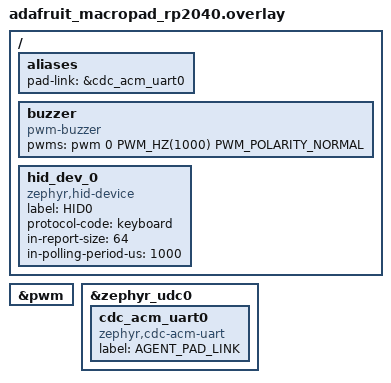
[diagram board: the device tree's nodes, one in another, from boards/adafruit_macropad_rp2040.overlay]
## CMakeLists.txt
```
# SPDX-License-Identifier: Apache-2.0

cmake_minimum_required(VERSION 3.20.0)
find_package(Zephyr REQUIRED HINTS $ENV{ZEPHYR_BASE})
project(agent_pad)

include(${ZEPHYR_BASE}/samples/subsys/usb/common/common.cmake)
target_sources(app PRIVATE
  src/main.c
  src/state.c
  src/keymap.c
  src/link.c
  src/ui.c
)

if(CONFIG_AGENT_PAD_SIM)
  target_sources(app PRIVATE src/sim.c)
else()
  target_sources(app PRIVATE
    src/hid_kb.c
    src/leds.c
    src/chime.c
    src/agent_pad_font_12.c
  )
endif()
```

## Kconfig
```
# SPDX-License-Identifier: Apache-2.0

config AGENT_PAD_SIM
	bool "Simulator GUI instead of pad hardware I/O"
	help
	  Replace the USB HID keyboard, LED strip and buzzer with an
	  interactive LVGL mock of the pad: clickable key and encoder
	  widgets, live agent-key colors and indicators for the keystrokes
	  and chimes the firmware would emit. The serial link protocol stays
	  active, making the whole application testable without hardware,
	  e.g. on qemu_x86.

# Source common USB sample options used to initialize new experimental USB
# device stack. The scope of these options is limited to USB samples in project
# tree, you cannot use them in your own application.
source "samples/subsys/usb/common/Kconfig.sample_usbd"

source "Kconfig.zephyr"
```

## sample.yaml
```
sample:
  name: Agent Pad
  description: Agent control surface with live status keys for AI coding agents
tests:
  sample.boards.adafruit.macropad_rp2040.agent_pad:
    build_only: true
    modules:
      - lvgl
    platform_allow:
      - adafruit_macropad_rp2040
    integration_platforms:
      - adafruit_macropad_rp2040
    tags:
      - usb
      - input
      - display
      - led_strip
  sample.boards.adafruit.macropad_rp2040.agent_pad.sim:
    build_only: true
    modules:
      - lvgl
    platform_allow:
      - qemu_x86
    integration_platforms:
      - qemu_x86
    tags:
      - display
      - input
```

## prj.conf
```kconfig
CONFIG_LOG=y

CONFIG_USB_DEVICE_STACK_NEXT=y
CONFIG_USBD_LOG_LEVEL_WRN=y
CONFIG_UDC_DRIVER_LOG_LEVEL_WRN=y
CONFIG_SAMPLE_USBD_PID=0x0007
CONFIG_SAMPLE_USBD_PRODUCT="Agent Pad"
CONFIG_HWINFO=y
CONFIG_UART_INTERRUPT_DRIVEN=y
CONFIG_UART_LINE_CTRL=y

CONFIG_GPIO=y
CONFIG_INPUT=y

CONFIG_SPI=y
CONFIG_DISPLAY=y

CONFIG_LVGL=y
CONFIG_LV_Z_MEM_POOL_SIZE=16384
CONFIG_LV_COLOR_DEPTH_1=y
# The SH1106 is vertically tiled, so LVGL can only flush whole 8-row pages.
# The default 10% rendering buffer is not even one page tall, which makes
# LVGL give up and leave the panel showing its uninitialized RAM. A full
# frame is only 1 KiB here, so render the whole screen at once.
CONFIG_LV_Z_VDB_SIZE=100
CONFIG_LV_USE_LABEL=y
# The UI draws with the 1 bpp agent_pad_font_12. LVGL still needs a default
# font to exist, so pick the smallest built-in one rather than link an
# antialiased face that nothing ends up rendering.
CONFIG_LV_FONT_DEFAULT_UNSCII_8=y

CONFIG_LED_STRIP=y

CONFIG_PWM=y
CONFIG_BUZZER=y
CONFIG_REGULATOR=y

CONFIG_HEAP_MEM_POOL_SIZE=4096
CONFIG_MAIN_STACK_SIZE=4096
CONFIG_SYSTEM_WORKQUEUE_STACK_SIZE=4096
```

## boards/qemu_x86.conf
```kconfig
CONFIG_AGENT_PAD_SIM=y

# No pad hardware in QEMU
CONFIG_USB_DEVICE_STACK_NEXT=n
CONFIG_SPI=n
CONFIG_LED_STRIP=n
CONFIG_PWM=n
CONFIG_BUZZER=n
CONFIG_REGULATOR=n
CONFIG_HWINFO=n

# The virtio tablet reports a burst of events at boot
CONFIG_INPUT_QUEUE_MAX_MSGS=64

# Color framebuffer, mouse-clickable widgets. The tiling constraint that
# forces a full-frame buffer on the OLED does not apply here, and a full
# 480x272 buffer at 32 bpp would be half a megabyte.
CONFIG_LV_COLOR_DEPTH_32=y
CONFIG_LV_Z_VDB_SIZE=10
# Greyscale is available here, so use the antialiased face instead of the
# 1 bpp font the OLED needs.
CONFIG_LV_FONT_MONTSERRAT_12=y
CONFIG_LV_FONT_DEFAULT_MONTSERRAT_12=y
CONFIG_LV_USE_BUTTON=y
CONFIG_LV_Z_POINTER_FROM_CHOSEN_TOUCH=y
CONFIG_LV_Z_MEM_POOL_SIZE=131072

# Wall-clock timing for interactive use; link protocol on the second
# serial port, exposed by QEMU as a pty
CONFIG_QEMU_ICOUNT=n
CONFIG_QEMU_EXTRA_FLAGS="-serial pty"
```

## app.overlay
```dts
/*
 * Copyright The Zephyr Project Contributors
 *
 * SPDX-License-Identifier: Apache-2.0
 */

#include <zephyr/dt-bindings/pwm/pwm.h>

/ {
	buzzer: buzzer {
		compatible = "pwm-buzzer";
		pwms = <&pwm 0 PWM_HZ(1000) PWM_POLARITY_NORMAL>;
	};

	hid_dev_0: hid_dev_0 {
		compatible = "zephyr,hid-device";
		label = "HID0";
		protocol-code = "keyboard";
		in-report-size = <64>;
		in-polling-period-us = <1000>;
	};
};

&pwm {
	status = "okay";
};

&zephyr_udc0 {
	cdc_acm_uart0: cdc_acm_uart0 {
		compatible = "zephyr,cdc-acm-uart";
		label = "AGENT_PAD_LINK";
	};
};
```

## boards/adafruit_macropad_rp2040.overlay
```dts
/*
 * Copyright The Zephyr Project Contributors
 *
 * SPDX-License-Identifier: Apache-2.0
 */

#include <zephyr/dt-bindings/pwm/pwm.h>

/ {
	aliases {
		pad-link = &cdc_acm_uart0;
	};

	buzzer: buzzer {
		compatible = "pwm-buzzer";
		pwms = <&pwm 0 PWM_HZ(1000) PWM_POLARITY_NORMAL>;
	};

	hid_dev_0: hid_dev_0 {
		compatible = "zephyr,hid-device";
		label = "HID0";
		protocol-code = "keyboard";
		in-report-size = <64>;
		in-polling-period-us = <1000>;
	};
};

&pwm {
	status = "okay";
};

&zephyr_udc0 {
	cdc_acm_uart0: cdc_acm_uart0 {
		compatible = "zephyr,cdc-acm-uart";
		label = "AGENT_PAD_LINK";
	};
};
```

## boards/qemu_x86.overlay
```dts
/*
 * Copyright The Zephyr Project Contributors
 *
 * SPDX-License-Identifier: Apache-2.0
 */

/ {
	aliases {
		pad-link = &uart1;
	};
};

/* Keep the framebuffer small so software rendering stays responsive. */
&ramfb0 {
	width = <480>;
	height = <272>;
};
```

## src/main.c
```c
/*
 * Copyright The Zephyr Project Contributors
 *
 * SPDX-License-Identifier: Apache-2.0
 */

#include <stdlib.h>

#include <zephyr/dt-bindings/input/input-event-codes.h>
#include <zephyr/input/input.h>
#include <zephyr/kernel.h>

#include <zephyr/logging/log.h>
LOG_MODULE_REGISTER(main, LOG_LEVEL_INF);

#include "agent_pad.h"

#define LAYER_HOLD_MS 600
#define CONFIRM_MS    3000

struct pad_event {
	uint16_t code;
	int32_t value;
};

K_MSGQ_DEFINE(pad_msgq, sizeof(struct pad_event), 8, 4);

static void input_cb(struct input_event *evt, void *user_data)
{
	struct pad_event pad_evt = {.code = evt->code, .value = evt->value};

	if (evt->type != INPUT_EV_KEY && evt->type != INPUT_EV_REL) {
		return;
	}

	if (k_msgq_put(&pad_msgq, &pad_evt, K_NO_WAIT) != 0) {
		LOG_WRN("Event queue full, dropped event");
	}
}

INPUT_CALLBACK_DEFINE(NULL, input_cb, NULL);

static void run_action(const struct key_action *action)
{
	state_note_set("%s", action->name);
	hid_kb_run(action);
}

static int armed_key = -1;

static void arm_clear(void)
{
	if (armed_key < 0) {
		return;
	}

	armed_key = -1;
	leds_arm(-1);
	state_disarm();
}

static void arm_expired(struct k_work *work)
{
	ARG_UNUSED(work);
	arm_clear();
}

static K_WORK_DELAYABLE_DEFINE(arm_work, arm_expired);

/*
 * Waits out a timeout that is already running, so that it cannot clear an arm
 * made moments later. Only safe to call from outside the work queue.
 */
static void disarm(void)
{
	struct k_work_sync sync;

	k_work_cancel_delayable_sync(&arm_work, &sync);
	arm_clear();
}

/*
 * The keys that type into the agent are armed by a first press and only run
 * on a second, so an unfamiliar layer can be read off the display without
 * firing anything. Pressing a different key arms that one instead.
 */
static void handle_action_key(int key)
{
	const struct key_action *action = &layers[state_layer()].keys[key - AGENT_SLOTS];
	bool confirmed = armed_key == key;

	leds_flash(key);
	disarm();

	if (confirmed) {
		run_action(action);
		return;
	}

	armed_key = key;
	leds_arm(key);
	state_arm(action->name);
	k_work_reschedule(&arm_work, K_MSEC(CONFIRM_MS));
}

static void handle_agent_key(int slot)
{
	struct agent agent;

	leds_flash(slot);
	link_notify_keypress(slot);

	state_agent_get(slot, &agent);
	if (agent.status == AGENT_DONE || agent.status == AGENT_INPUT ||
	    agent.status == AGENT_ERROR) {
		state_agent_set(slot, AGENT_IDLE, NULL);
		state_note_set("A%d ack", slot + 1);
	}
}

static void handle_encoder_button(int32_t value)
{
	static int64_t pressed_at;

	if (value != 0) {
		pressed_at = k_uptime_get();
		return;
	}

	if (k_uptime_get() - pressed_at >= LAYER_HOLD_MS) {
		/* The armed key means something else on the next layer. */
		disarm();
		state_layer_next();
		state_note_set("%s", layers[state_layer()].name);
		chime_play(CHIME_LAYER);
	} else {
		run_action(&layers[state_layer()].enc_press);
	}
}

static int key_index(uint16_t code)
{
	for (int i = 0; i < (int)ARRAY_SIZE(pad_key_codes); i++) {
		if (pad_key_codes[i] == code) {
			return i;
		}
	}

	return -1;
}

static void handle_event(const struct pad_event *evt)
{
	const struct layer *layer = &layers[state_layer()];
	int key = key_index(evt->code);

	if (key >= 0) {
		if (evt->value == 0) {
			return;
		}
		if (key < AGENT_SLOTS) {
			handle_agent_key(key);
		} else {
			handle_action_key(key);
		}
		return;
	}

	switch (evt->code) {
	case INPUT_KEY_ENTER:
		handle_encoder_button(evt->value);
		break;
	case INPUT_REL_WHEEL:
		for (int i = 0; i < abs(evt->value); i++) {
			run_action(evt->value > 0 ? &layer->enc_cw : &layer->enc_ccw);
		}
		break;
	default:
		break;
	}
}

/*
 * Everything here is optional: a pad with no USB host still shows agent
 * status, and one with a dead speaker still types. Failures are reported on
 * the display rather than taken as fatal.
 */
static const struct {
	const char *name;
	int (*init)(void);
} subsystems[] = {
	{"usb", hid_kb_init},
	{"link", link_init},
	{"leds", leds_init},
	{"audio", chime_init},
};

int main(void)
{
	struct pad_event evt;

	/*
	 * The display is the only output that does not need a host, so it
	 * comes up first and is the one hard dependency.
	 */
	if (ui_init() != 0) {
		return -EIO;
	}

	for (size_t i = 0; i < ARRAY_SIZE(subsystems); i++) {
		int ret = subsystems[i].init();

		if (ret != 0) {
			LOG_WRN("%s unavailable (%d)", subsystems[i].name, ret);
			state_note_set("no %s %d", subsystems[i].name, ret);
		}
	}

	LOG_INF("Agent pad ready");

	while (true) {
		k_msgq_get(&pad_msgq, &evt, K_FOREVER);
		handle_event(&evt);
	}

	return 0;
}
```

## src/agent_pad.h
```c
/*
 * Copyright The Zephyr Project Contributors
 *
 * SPDX-License-Identifier: Apache-2.0
 */

#ifndef AGENT_PAD_H_
#define AGENT_PAD_H_

#include <stdbool.h>
#include <stddef.h>
#include <stdint.h>

#define AGENT_SLOTS	6
#define AGENT_LABEL_LEN	12
#define NOTE_LEN	13

enum agent_status {
	AGENT_EMPTY,
	AGENT_IDLE,
	AGENT_THINKING,
	AGENT_DONE,
	AGENT_INPUT,
	AGENT_ERROR,
};

struct agent {
	enum agent_status status;
	char label[AGENT_LABEL_LEN];
};

enum agent_status state_agent_set(int slot, enum agent_status status, const char *label);
void state_agent_get(int slot, struct agent *out);
bool state_all_empty(void);
int state_layer(void);
void state_layer_next(void);
void state_note_set(const char *fmt, ...);
void state_note_get(char *out, size_t len);
void state_arm(const char *name);
void state_disarm(void);
bool state_armed(void);
uint32_t state_seq(void);

struct key_tap {
	uint8_t mod;
	uint8_t code;
};

struct key_action {
	const char *name;
	const struct key_tap *taps;
	size_t num_taps;
	const char *text;
};

struct layer {
	const char *name;
	uint8_t color[3];
	struct key_action keys[6];
	struct key_action enc_cw;
	struct key_action enc_ccw;
	struct key_action enc_press;
};

extern const struct layer layers[];
extern const size_t num_layers;
extern const uint16_t pad_key_codes[12];

int hid_kb_init(void);
void hid_kb_run(const struct key_action *action);

int link_init(void);
void link_notify_keypress(int slot);

int leds_init(void);
void leds_flash(int key);
void leds_arm(int key);

int ui_init(void);

enum chime {
	CHIME_DONE,
	CHIME_INPUT,
	CHIME_ERROR,
	CHIME_LAYER,
};

int chime_init(void);
void chime_play(enum chime chime);

#endif /* AGENT_PAD_H_ */
```

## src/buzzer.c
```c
/*
 * Copyright The Zephyr Project Contributors
 *
 * SPDX-License-Identifier: Apache-2.0
 */

#include <zephyr/device.h>
#include <zephyr/drivers/pwm.h>
#include <zephyr/drivers/regulator.h>
#include <zephyr/kernel.h>

#include <zephyr/logging/log.h>
LOG_MODULE_REGISTER(buzzer, LOG_LEVEL_INF);

#include "agent_pad.h"

#define SPEAKER_PWM_CHANNEL 0
#define MAX_NOTES 3

struct note {
	uint16_t freq_hz;
	uint16_t duration_ms;
};

static const struct note chimes[][MAX_NOTES] = {
	[CHIME_DONE] = {{1568, 70}},
	[CHIME_INPUT] = {{880, 70}, {1175, 110}},
	[CHIME_ERROR] = {{196, 120}, {0, 30}, {196, 120}},
	[CHIME_LAYER] = {{1319, 40}},
};

static const struct device *pwm_dev = DEVICE_DT_GET(DT_NODELABEL(pwm));
static const struct device *speaker_reg = DEVICE_DT_GET(DT_NODELABEL(speaker_reg));

static const struct note *current;
static int note_idx;

static void play_note(struct k_work *work);
static K_WORK_DELAYABLE_DEFINE(note_work, play_note);

static void tone(uint16_t freq_hz)
{
	if (freq_hz == 0) {
		pwm_set(pwm_dev, SPEAKER_PWM_CHANNEL, PWM_HZ(100), 0, 0);
		return;
	}

	pwm_set(pwm_dev, SPEAKER_PWM_CHANNEL, PWM_HZ(freq_hz), PWM_HZ(freq_hz) / 8, 0);
}

static void play_note(struct k_work *work)
{
	if (current == NULL || note_idx >= MAX_NOTES || current[note_idx].duration_ms == 0) {
		tone(0);
		current = NULL;
		return;
	}

	tone(current[note_idx].freq_hz);
	k_work_schedule(&note_work, K_MSEC(current[note_idx].duration_ms));
	note_idx++;
}

void buzzer_play(enum chime chime)
{
	if (current != NULL) {
		return;
	}

	current = chimes[chime];
	note_idx = 0;
	k_work_schedule(&note_work, K_NO_WAIT);
}

int buzzer_init(void)
{
	if (!device_is_ready(pwm_dev) || !device_is_ready(speaker_reg)) {
		LOG_ERR("Speaker devices not ready");
		return -EIO;
	}

	return regulator_enable(speaker_reg);
}
```

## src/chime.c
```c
/*
 * Copyright The Zephyr Project Contributors
 *
 * SPDX-License-Identifier: Apache-2.0
 */

#include <zephyr/device.h>
#include <zephyr/drivers/buzzer.h>
#include <zephyr/drivers/regulator.h>
#include <zephyr/kernel.h>

#include <zephyr/logging/log.h>
LOG_MODULE_REGISTER(chime, LOG_LEVEL_INF);

#include "agent_pad.h"

#define VOLUME_PERCENT 25
#define MAX_NOTES 3

struct note {
	uint16_t freq_hz;
	uint16_t duration_ms;
};

static const struct note chimes[][MAX_NOTES] = {
	[CHIME_DONE] = {{1568, 70}},
	[CHIME_INPUT] = {{880, 70}, {1175, 110}},
	[CHIME_ERROR] = {{196, 120}, {BUZZER_FREQ_REST, 30}, {196, 120}},
	[CHIME_LAYER] = {{1319, 40}},
};

static const struct device *buzzer = DEVICE_DT_GET(DT_NODELABEL(buzzer));
static const struct device *speaker_reg = DEVICE_DT_GET(DT_NODELABEL(speaker_reg));

static const struct note *current;
static int note_idx;
static bool ready;

static void play_note(struct k_work *work);
static K_WORK_DELAYABLE_DEFINE(note_work, play_note);

static void play_note(struct k_work *work)
{
	const struct note *note;

	if (current == NULL || note_idx >= MAX_NOTES || current[note_idx].duration_ms == 0) {
		current = NULL;
		return;
	}

	note = &current[note_idx++];
	buzzer_tone(buzzer, note->freq_hz, note->duration_ms);
	k_work_schedule(&note_work, K_MSEC(note->duration_ms));
}

void chime_play(enum chime chime)
{
	if (!ready || current != NULL) {
		return;
	}

	current = chimes[chime];
	note_idx = 0;
	k_work_schedule(&note_work, K_NO_WAIT);
}

int chime_init(void)
{
	int ret;

	if (!device_is_ready(buzzer) || !device_is_ready(speaker_reg)) {
		LOG_ERR("Speaker devices not ready");
		return -EIO;
	}

	buzzer_set_volume(buzzer, VOLUME_PERCENT);

	ret = regulator_enable(speaker_reg);
	if (ret != 0) {
		return ret;
	}

	ready = true;

	return 0;
}
```

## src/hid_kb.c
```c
/*
 * Copyright The Zephyr Project Contributors
 *
 * SPDX-License-Identifier: Apache-2.0
 */

#include <sample_usbd.h>

#include <zephyr/kernel.h>
#include <zephyr/usb/class/hid.h>
#include <zephyr/usb/class/usbd_hid.h>
#include <zephyr/usb/usbd.h>

#include <zephyr/logging/log.h>
LOG_MODULE_REGISTER(hid_kb, LOG_LEVEL_INF);

#include "agent_pad.h"

#define REPORT_SIZE 8

static const uint8_t hid_report_desc[] = HID_KEYBOARD_REPORT_DESC();

static const struct device *hid_dev;
static bool kb_ready;

UDC_STATIC_BUF_DEFINE(report, REPORT_SIZE);
static K_SEM_DEFINE(report_sem, 1, 1);

static void iface_ready(const struct device *dev, const bool ready)
{
	kb_ready = ready;
}

static void input_report_done(const struct device *dev, const uint8_t *const buf)
{
	k_sem_give(&report_sem);
}

static int get_report(const struct device *dev, const uint8_t type, const uint8_t id,
		      const uint16_t len, uint8_t *const buf)
{
	return 0;
}

static int set_report(const struct device *dev, const uint8_t type, const uint8_t id,
		      const uint16_t len, const uint8_t *const buf)
{
	return 0;
}

/*
 * Required because "keyboard" protocol-code declares a boot interface.
 * HID_KEYBOARD_REPORT_DESC() already is the boot layout, so the report
 * format is the same under either protocol and nothing has to change.
 */
static void set_protocol(const struct device *dev, const uint8_t proto)
{
	LOG_DBG("Protocol set to %s", proto == 0U ? "boot" : "report");
}

static const struct hid_device_ops kb_ops = {
	.iface_ready = iface_ready,
	.input_report_done = input_report_done,
	.get_report = get_report,
	.set_report = set_report,
	.set_protocol = set_protocol,
};

static void submit(uint8_t mod, uint8_t code)
{
	memset(report, 0, REPORT_SIZE);
	report[0] = mod;
	report[2] = code;

	if (k_sem_take(&report_sem, K_MSEC(100)) != 0) {
		k_sem_give(&report_sem);
		return;
	}

	if (hid_device_submit_report(hid_dev, REPORT_SIZE, report) != 0) {
		k_sem_give(&report_sem);
	}
}

static void tap(uint8_t mod, uint8_t code)
{
	submit(mod, code);
	submit(0, 0);
}

static bool char_to_tap(char c, uint8_t *mod, uint8_t *code)
{
	static const struct {
		char c;
		uint8_t mod;
		uint8_t code;
	} table[] = {
		{' ', 0, HID_KEY_SPACE},   {'\n', 0, HID_KEY_ENTER},
		{'.', 0, HID_KEY_DOT},	   {',', 0, HID_KEY_COMMA},
		{'-', 0, HID_KEY_MINUS},   {'/', 0, HID_KEY_SLASH},
		{'!', HID_KBD_MODIFIER_LEFT_SHIFT, HID_KEY_1},
		{'#', HID_KBD_MODIFIER_LEFT_SHIFT, HID_KEY_3},
		{'?', HID_KBD_MODIFIER_LEFT_SHIFT, HID_KEY_SLASH},
		{'_', HID_KBD_MODIFIER_LEFT_SHIFT, HID_KEY_MINUS},
	};

	*mod = 0;

	if (c >= 'a' && c <= 'z') {
		*code = HID_KEY_A + (c - 'a');
		return true;
	}
	if (c >= 'A' && c <= 'Z') {
		*mod = HID_KBD_MODIFIER_LEFT_SHIFT;
		*code = HID_KEY_A + (c - 'A');
		return true;
	}
	if (c >= '1' && c <= '9') {
		*code = HID_KEY_1 + (c - '1');
		return true;
	}
	if (c == '0') {
		*code = HID_KEY_0;
		return true;
	}

	for (size_t i = 0; i < ARRAY_SIZE(table); i++) {
		if (table[i].c == c) {
			*mod = table[i].mod;
			*code = table[i].code;
			return true;
		}
	}

	return false;
}

void hid_kb_run(const struct key_action *action)
{
	if (!kb_ready) {
		return;
	}

	if (action->taps != NULL) {
		for (size_t i = 0; i < action->num_taps; i++) {
			tap(action->taps[i].mod, action->taps[i].code);
		}
		return;
	}

	for (const char *c = action->text; *c != '\0'; c++) {
		uint8_t mod, code;

		if (char_to_tap(*c, &mod, &code)) {
			tap(mod, code);
		}
	}
}

int hid_kb_init(void)
{
	struct usbd_context *usbd;
	int ret;

	hid_dev = DEVICE_DT_GET_ONE(zephyr_hid_device);
	if (!device_is_ready(hid_dev)) {
		LOG_ERR("HID device not ready");
		return -EIO;
	}

	ret = hid_device_register(hid_dev, hid_report_desc, sizeof(hid_report_desc), &kb_ops);
	if (ret != 0) {
		LOG_ERR("Failed to register HID device, %d", ret);
		return ret;
	}

	usbd = sample_usbd_init_device(NULL);
	if (usbd == NULL) {
		LOG_ERR("Failed to initialize USB device");
		return -EIO;
	}

	if (!usbd_can_detect_vbus(usbd)) {
		ret = usbd_enable(usbd);
		if (ret != 0) {
			LOG_ERR("Failed to enable USB device, %d", ret);
			return ret;
		}
	}

	return 0;
}
```

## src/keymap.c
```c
/*
 * Copyright The Zephyr Project Contributors
 *
 * SPDX-License-Identifier: Apache-2.0
 */

#include <zephyr/dt-bindings/input/input-event-codes.h>
#include <zephyr/usb/class/hid.h>

#include "agent_pad.h"

const uint16_t pad_key_codes[12] = {
	INPUT_KEY_F1, INPUT_KEY_F2,  INPUT_KEY_F3,  INPUT_KEY_F4,
	INPUT_KEY_F5, INPUT_KEY_F6,  INPUT_KEY_F7,  INPUT_KEY_F8,
	INPUT_KEY_F9, INPUT_KEY_F10, INPUT_KEY_F11, INPUT_KEY_F12,
};

#define NUM(_a) (sizeof(_a) / sizeof((_a)[0]))

#define TAPS(_name, ...)						\
	static const struct key_tap _name[] = {__VA_ARGS__}

#define KEY_TAPS(_label, _taps)						\
	{.name = _label, .taps = _taps, .num_taps = NUM(_taps)}

#define KEY_TEXT(_label, _text)						\
	{.name = _label, .text = _text}

TAPS(tap_esc, {0, HID_KEY_ESC});
TAPS(tap_mode, {HID_KBD_MODIFIER_LEFT_SHIFT, HID_KEY_TAB});
TAPS(tap_transcript, {HID_KBD_MODIFIER_LEFT_CTRL, HID_KEY_R});
TAPS(tap_up, {0, HID_KEY_UP});
TAPS(tap_down, {0, HID_KEY_DOWN});
TAPS(tap_enter, {0, HID_KEY_ENTER});

const struct layer layers[] = {
	{
		.name = "CLAUDE",
		.color = {0xff, 0x50, 0x00},
		.keys = {
			KEY_TAPS("stop", tap_esc),
			KEY_TAPS("mode", tap_mode),
			KEY_TAPS("verbose", tap_transcript),
			KEY_TAPS("history", tap_up),
			KEY_TAPS("accept", tap_enter),
			KEY_TEXT("claude", "claude\n"),
		},
		.enc_cw = KEY_TAPS("down", tap_down),
		.enc_ccw = KEY_TAPS("up", tap_up),
		.enc_press = KEY_TAPS("enter", tap_enter),
	},
	{
		.name = "SLASH",
		.color = {0x00, 0x50, 0xff},
		.keys = {
			KEY_TEXT("/compact", "/compact\n"),
			KEY_TEXT("/clear", "/clear\n"),
			KEY_TEXT("/model", "/model\n"),
			KEY_TEXT("/resume", "/resume\n"),
			KEY_TEXT("/review", "/review\n"),
			KEY_TEXT("/help", "/help\n"),
		},
		.enc_cw = KEY_TAPS("down", tap_down),
		.enc_ccw = KEY_TAPS("up", tap_up),
		.enc_press = KEY_TAPS("enter", tap_enter),
	},
};

const size_t num_layers = NUM(layers);
```

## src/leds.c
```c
/*
 * Copyright The Zephyr Project Contributors
 *
 * SPDX-License-Identifier: Apache-2.0
 */

#include <zephyr/device.h>
#include <zephyr/drivers/led_strip.h>
#include <zephyr/kernel.h>

#include <zephyr/logging/log.h>
LOG_MODULE_REGISTER(leds, LOG_LEVEL_INF);

#include "agent_pad.h"

#define NUM_PIXELS   12
#define FRAME_MS     33
#define FLASH_MS     120
#define LAYER_DIM    8

static const struct device *strip = DEVICE_DT_GET(DT_ALIAS(led_strip));

static struct led_rgb pixels[NUM_PIXELS];
static int64_t flash_until[NUM_PIXELS];
static int armed_key = -1;

/* Triangle wave, 0..255 over the given period. */
static uint8_t wave(int64_t t, uint32_t period_ms)
{
	uint32_t phase = (t % period_ms) * 512U / period_ms;

	return (phase < 256U) ? phase : 511U - phase;
}

static struct led_rgb scale(uint8_t r, uint8_t g, uint8_t b, uint8_t level)
{
	return (struct led_rgb){
		.r = (uint16_t)r * level / 255U,
		.g = (uint16_t)g * level / 255U,
		.b = (uint16_t)b * level / 255U,
	};
}

static struct led_rgb agent_pixel(const struct agent *agent, int64_t t)
{
	switch (agent->status) {
	case AGENT_IDLE:
		return scale(0xff, 0xff, 0xff, 12);
	case AGENT_THINKING:
		return scale(0x00, 0x60, 0xff, 20 + wave(t, 2000) / 4);
	case AGENT_DONE:
		return scale(0x00, 0xff, 0x20, 60);
	case AGENT_INPUT:
		return scale(0xff, 0x70, 0x00, 20 + wave(t, 800) / 3);
	case AGENT_ERROR:
		return scale(0xff, 0x00, 0x00, (t % 500) < 250 ? 80 : 10);
	default:
		return scale(0, 0, 0, 0);
	}
}

/* Soft white comet slowly sweeping the agent keys while nothing is connected. */
static struct led_rgb idle_pixel(int i, int64_t t)
{
	int head = (t / 400) % AGENT_SLOTS;
	int dist = (i - head + AGENT_SLOTS) % AGENT_SLOTS;

	return scale(0xff, 0xff, 0xff, dist == 0 ? 25 : (dist == 1 ? 8 : 0));
}

static void render(int64_t t)
{
	const struct layer *layer = &layers[state_layer()];
	bool empty = state_all_empty();
	struct agent agent;

	for (int i = 0; i < AGENT_SLOTS; i++) {
		if (empty) {
			pixels[i] = idle_pixel(i, t);
		} else {
			state_agent_get(i, &agent);
			pixels[i] = agent_pixel(&agent, t);
		}
	}

	for (int i = AGENT_SLOTS; i < NUM_PIXELS; i++) {
		pixels[i] = scale(layer->color[0], layer->color[1], layer->color[2], LAYER_DIM);
	}

	/* Pulse the key waiting for its confirming press. */
	if (armed_key >= 0) {
		pixels[armed_key] = scale(0xff, 0xff, 0xff, 40 + wave(t, 400) / 2);
	}

	for (int i = 0; i < NUM_PIXELS; i++) {
		if (t < flash_until[i]) {
			pixels[i] = scale(0xff, 0xff, 0xff, 100);
		}
	}
}

void leds_arm(int key)
{
	armed_key = (key >= 0 && key < NUM_PIXELS) ? key : -1;
}

void leds_flash(int key)
{
	if (key >= 0 && key < NUM_PIXELS) {
		flash_until[key] = k_uptime_get() + FLASH_MS;
	}
}

static void leds_thread(void *p1, void *p2, void *p3)
{
	while (true) {
		render(k_uptime_get());
		led_strip_update_rgb(strip, pixels, NUM_PIXELS);
		k_msleep(FRAME_MS);
	}
}

K_THREAD_DEFINE(leds_tid, 1024, leds_thread, NULL, NULL, NULL, 7, 0, K_TICKS_FOREVER);

int leds_init(void)
{
	if (!device_is_ready(strip)) {
		LOG_ERR("LED strip device not ready");
		return -EIO;
	}

	k_thread_start(leds_tid);

	return 0;
}
```

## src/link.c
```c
/*
 * Copyright The Zephyr Project Contributors
 *
 * SPDX-License-Identifier: Apache-2.0
 */

#include <stdio.h>
#include <stdlib.h>
#include <string.h>

#include <zephyr/device.h>
#include <zephyr/drivers/uart.h>
#include <zephyr/kernel.h>

#include <zephyr/logging/log.h>
LOG_MODULE_REGISTER(link, LOG_LEVEL_INF);

#include "agent_pad.h"

#define LINE_LEN 64

static const struct device *uart_dev = DEVICE_DT_GET(DT_ALIAS(pad_link));

static char rx_line[LINE_LEN];
static size_t rx_len;
static bool ready;

K_MSGQ_DEFINE(line_msgq, LINE_LEN, 8, 4);

static void link_send(const char *line)
{
	uint32_t dtr;

	if (!ready) {
		return;
	}

	/* Skip when a DTR-capable port (CDC ACM) has no terminal attached. */
	if (uart_line_ctrl_get(uart_dev, UART_LINE_CTRL_DTR, &dtr) == 0 && dtr == 0U) {
		return;
	}

	while (*line != '\0') {
		uart_poll_out(uart_dev, *line++);
	}
	uart_poll_out(uart_dev, '\n');
}

void link_notify_keypress(int slot)
{
	char line[16];

	snprintf(line, sizeof(line), "key %d", slot + 1);
	link_send(line);
}

static bool parse_status(const char *word, enum agent_status *status)
{
	static const struct {
		const char *word;
		enum agent_status status;
	} map[] = {
		{"idle", AGENT_IDLE},	  {"thinking", AGENT_THINKING},
		{"busy", AGENT_THINKING}, {"done", AGENT_DONE},
		{"input", AGENT_INPUT},	  {"error", AGENT_ERROR},
	};

	for (size_t i = 0; i < ARRAY_SIZE(map); i++) {
		if (strcmp(word, map[i].word) == 0) {
			*status = map[i].status;
			return true;
		}
	}

	return false;
}

static void status_effects(int slot, enum agent_status old, enum agent_status status)
{
	if (status == old) {
		return;
	}

	switch (status) {
	case AGENT_DONE:
		state_note_set("A%d done", slot + 1);
		chime_play(CHIME_DONE);
		break;
	case AGENT_INPUT:
		state_note_set("A%d needs you", slot + 1);
		chime_play(CHIME_INPUT);
		break;
	case AGENT_ERROR:
		state_note_set("A%d error", slot + 1);
		chime_play(CHIME_ERROR);
		break;
	case AGENT_THINKING:
		state_note_set("A%d thinking", slot + 1);
		break;
	default:
		break;
	}
}

static void handle_line(char *line)
{
	char *saveptr;
	char *cmd = strtok_r(line, " ", &saveptr);

	if (cmd == NULL) {
		return;
	}

	if (strcmp(cmd, "agent") == 0) {
		char *slot_str = strtok_r(NULL, " ", &saveptr);
		char *status_str = strtok_r(NULL, " ", &saveptr);
		char *label = strtok_r(NULL, "", &saveptr);
		enum agent_status status;
		int slot;

		if (slot_str == NULL || status_str == NULL) {
			return;
		}

		slot = atoi(slot_str) - 1;
		if (slot < 0 || slot >= AGENT_SLOTS || !parse_status(status_str, &status)) {
			return;
		}

		status_effects(slot, state_agent_set(slot, status, label), status);
	} else if (strcmp(cmd, "clear") == 0) {
		char *slot_str = strtok_r(NULL, " ", &saveptr);

		if (slot_str == NULL || strcmp(slot_str, "all") == 0) {
			for (int i = 0; i < AGENT_SLOTS; i++) {
				state_agent_set(i, AGENT_EMPTY, NULL);
			}
		} else {
			state_agent_set(atoi(slot_str) - 1, AGENT_EMPTY, NULL);
		}
	} else if (strcmp(cmd, "ping") == 0) {
		link_send("pong");
	}
}

static void line_work_handler(struct k_work *work)
{
	char line[LINE_LEN];

	while (k_msgq_get(&line_msgq, line, K_NO_WAIT) == 0) {
		handle_line(line);
	}
}

static K_WORK_DEFINE(line_work, line_work_handler);

static void uart_cb(const struct device *dev, void *user_data)
{
	uint8_t c;

	uart_irq_update(dev);

	while (uart_irq_rx_ready(dev) && uart_fifo_read(dev, &c, 1) == 1) {
		if (c == '\n' || c == '\r') {
			if (rx_len > 0) {
				rx_line[rx_len] = '\0';
				k_msgq_put(&line_msgq, rx_line, K_NO_WAIT);
				k_work_submit(&line_work);
				rx_len = 0;
			}
		} else if (rx_len < LINE_LEN - 1) {
			rx_line[rx_len++] = c;
		}
	}
}

int link_init(void)
{
	if (!device_is_ready(uart_dev)) {
		LOG_ERR("CDC ACM device not ready");
		return -EIO;
	}

	uart_irq_callback_set(uart_dev, uart_cb);
	uart_irq_rx_enable(uart_dev);
	ready = true;

	return 0;
}
```

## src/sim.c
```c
/*
 * Copyright The Zephyr Project Contributors
 *
 * SPDX-License-Identifier: Apache-2.0
 */

#include <stdio.h>

#include <lvgl.h>
#include <zephyr/dt-bindings/input/input-event-codes.h>
#include <zephyr/input/input.h>
#include <zephyr/kernel.h>

#include <zephyr/logging/log.h>
LOG_MODULE_REGISTER(sim, LOG_LEVEL_INF);

#include "agent_pad.h"

#define KEY_W	 82
#define KEY_H	 52
#define KEY_GAP	 8
#define PAD_X	 210
#define MARGIN	 18

lv_obj_t *sim_build(lv_obj_t *root);

static lv_obj_t *keys[12];
static int armed_key = -1;
static lv_obj_t *key_labels[12];
static lv_obj_t *sent_label;
static lv_obj_t *chime_label;

static char sent_text[32] = "sent: -";
static char chime_text[32] = "chime: -";

int hid_kb_init(void)
{
	return 0;
}

void hid_kb_run(const struct key_action *action)
{
	snprintf(sent_text, sizeof(sent_text), "sent: %s", action->name);
}

int leds_init(void)
{
	return 0;
}

void leds_flash(int key)
{
	ARG_UNUSED(key);
}

void leds_arm(int key)
{
	armed_key = (key >= 0 && key < (int)ARRAY_SIZE(keys)) ? key : -1;
}

int chime_init(void)
{
	return 0;
}

void chime_play(enum chime chime)
{
	static const char *const names[] = {
		[CHIME_DONE] = "done",
		[CHIME_INPUT] = "input",
		[CHIME_ERROR] = "error",
		[CHIME_LAYER] = "layer",
	};

	snprintf(chime_text, sizeof(chime_text), "chime: %s", names[chime]);
}

static lv_color_t status_color(enum agent_status status)
{
	switch (status) {
	case AGENT_IDLE:
		return lv_color_make(0x60, 0x60, 0x60);
	case AGENT_THINKING:
		return lv_color_make(0x30, 0x78, 0xff);
	case AGENT_DONE:
		return lv_color_make(0x28, 0xc8, 0x5a);
	case AGENT_INPUT:
		return lv_color_make(0xff, 0xaa, 0x28);
	case AGENT_ERROR:
		return lv_color_make(0xe6, 0x3c, 0x3c);
	default:
		return lv_color_make(0x23, 0x26, 0x2c);
	}
}

static void key_event_cb(lv_event_t *e)
{
	int idx = (int)(intptr_t)lv_event_get_user_data(e);
	lv_event_code_t code = lv_event_get_code(e);

	if (code == LV_EVENT_PRESSED) {
		input_report_key(NULL, pad_key_codes[idx], 1, true, K_NO_WAIT);
	} else if (code == LV_EVENT_RELEASED || code == LV_EVENT_PRESS_LOST) {
		input_report_key(NULL, pad_key_codes[idx], 0, true, K_NO_WAIT);
	}
}

static void knob_event_cb(lv_event_t *e)
{
	lv_event_code_t code = lv_event_get_code(e);

	if (code == LV_EVENT_PRESSED) {
		input_report_key(NULL, INPUT_KEY_ENTER, 1, true, K_NO_WAIT);
	} else if (code == LV_EVENT_RELEASED || code == LV_EVENT_PRESS_LOST) {
		input_report_key(NULL, INPUT_KEY_ENTER, 0, true, K_NO_WAIT);
	}
}

static void turn_event_cb(lv_event_t *e)
{
	input_report_rel(NULL, INPUT_REL_WHEEL, (int)(intptr_t)lv_event_get_user_data(e), true,
			 K_NO_WAIT);
}

static void sim_timer_cb(lv_timer_t *timer)
{
	const struct layer *layer = &layers[state_layer()];
	struct agent agent;

	for (int i = 0; i < AGENT_SLOTS; i++) {
		state_agent_get(i, &agent);
		lv_obj_set_style_bg_color(keys[i], status_color(agent.status), 0);
	}

	for (int i = 0; i < 6; i++) {
		lv_obj_set_style_bg_color(keys[AGENT_SLOTS + i],
					  lv_color_make(layer->color[0] / 3, layer->color[1] / 3,
							layer->color[2] / 3),
					  0);
		lv_label_set_text(key_labels[AGENT_SLOTS + i], layer->keys[i].name);
	}

	/* Mirror the pad's pulse on the key waiting to be confirmed. */
	if (armed_key >= 0) {
		lv_obj_set_style_bg_color(keys[armed_key], lv_color_white(), 0);
	}

	lv_label_set_text(sent_label, sent_text);
	lv_label_set_text(chime_label, chime_text);
}

static lv_obj_t *make_button(lv_obj_t *parent, const char *text, lv_event_cb_t cb, intptr_t arg,
			     lv_obj_t **label_out)
{
	lv_obj_t *btn = lv_button_create(parent);
	lv_obj_t *label = lv_label_create(btn);

	lv_label_set_text(label, text);
	lv_obj_center(label);
	lv_obj_add_event_cb(btn, cb, LV_EVENT_ALL, (void *)arg);
	if (label_out != NULL) {
		*label_out = label;
	}

	return btn;
}

lv_obj_t *sim_build(lv_obj_t *root)
{
	lv_obj_t *oled;
	lv_obj_t *btn;

	lv_obj_set_style_bg_color(root, lv_color_make(0x14, 0x16, 0x1a), 0);
	lv_obj_set_style_bg_opa(root, LV_OPA_COVER, 0);

	oled = lv_obj_create(root);
	lv_obj_remove_style_all(oled);
	lv_obj_set_pos(oled, MARGIN, MARGIN);
	lv_obj_set_size(oled, 128, 64);
	lv_obj_set_style_outline_width(oled, 2, 0);
	lv_obj_set_style_outline_pad(oled, 3, 0);
	lv_obj_set_style_outline_color(oled, lv_color_make(0x40, 0x46, 0x50), 0);

	sent_label = lv_label_create(root);
	lv_obj_set_pos(sent_label, MARGIN, 110);
	lv_obj_set_style_text_color(sent_label, lv_color_white(), 0);

	chime_label = lv_label_create(root);
	lv_obj_set_pos(chime_label, MARGIN, 130);
	lv_obj_set_style_text_color(chime_label, lv_color_make(0x8b, 0x93, 0xa1), 0);

	btn = make_button(root, LV_SYMBOL_LEFT, turn_event_cb, -1, NULL);
	lv_obj_set_pos(btn, MARGIN, 170);
	lv_obj_set_size(btn, 44, 40);

	btn = make_button(root, "KNOB", knob_event_cb, 0, NULL);
	lv_obj_set_pos(btn, MARGIN + 52, 170);
	lv_obj_set_size(btn, 60, 40);

	btn = make_button(root, LV_SYMBOL_RIGHT, turn_event_cb, 1, NULL);
	lv_obj_set_pos(btn, MARGIN + 120, 170);
	lv_obj_set_size(btn, 44, 40);

	for (int i = 0; i < 12; i++) {
		char text[4];

		snprintf(text, sizeof(text), "A%d", i + 1);
		btn = make_button(root, i < AGENT_SLOTS ? text : "", key_event_cb, i,
				  &key_labels[i]);
		lv_obj_set_pos(btn, PAD_X + (i % 3) * (KEY_W + KEY_GAP),
			       MARGIN + (i / 3) * (KEY_H + KEY_GAP));
		lv_obj_set_size(btn, KEY_W, KEY_H);
		lv_obj_set_style_radius(btn, 6, 0);
		keys[i] = btn;
	}

	lv_timer_create(sim_timer_cb, 150, NULL);

	return oled;
}
```

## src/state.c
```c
/*
 * Copyright The Zephyr Project Contributors
 *
 * SPDX-License-Identifier: Apache-2.0
 */

#include <stdarg.h>
#include <stdio.h>
#include <string.h>

#include <zephyr/kernel.h>

#include "agent_pad.h"

static struct agent agents[AGENT_SLOTS];
static int layer;
static char note[NOTE_LEN];
static bool armed;
static atomic_t seq;

static K_MUTEX_DEFINE(lock);

static void bump(void)
{
	atomic_inc(&seq);
}

enum agent_status state_agent_set(int slot, enum agent_status status, const char *label)
{
	enum agent_status old;

	if (slot < 0 || slot >= AGENT_SLOTS) {
		return AGENT_EMPTY;
	}

	k_mutex_lock(&lock, K_FOREVER);
	old = agents[slot].status;
	agents[slot].status = status;
	if (label != NULL) {
		strncpy(agents[slot].label, label, AGENT_LABEL_LEN - 1);
		agents[slot].label[AGENT_LABEL_LEN - 1] = '\0';
	} else if (status == AGENT_EMPTY) {
		agents[slot].label[0] = '\0';
	}
	k_mutex_unlock(&lock);

	bump();

	return old;
}

void state_agent_get(int slot, struct agent *out)
{
	k_mutex_lock(&lock, K_FOREVER);
	*out = agents[slot];
	k_mutex_unlock(&lock);
}

bool state_all_empty(void)
{
	bool empty = true;

	k_mutex_lock(&lock, K_FOREVER);
	for (int i = 0; i < AGENT_SLOTS; i++) {
		if (agents[i].status != AGENT_EMPTY) {
			empty = false;
			break;
		}
	}
	k_mutex_unlock(&lock);

	return empty;
}

int state_layer(void)
{
	return layer;
}

void state_layer_next(void)
{
	layer = (layer + 1) % num_layers;
	bump();
}

void state_note_set(const char *fmt, ...)
{
	va_list ap;

	k_mutex_lock(&lock, K_FOREVER);
	va_start(ap, fmt);
	vsnprintf(note, sizeof(note), fmt, ap);
	va_end(ap);
	k_mutex_unlock(&lock);

	bump();
}

void state_arm(const char *name)
{
	k_mutex_lock(&lock, K_FOREVER);
	armed = true;
	snprintf(note, sizeof(note), "%s?", name);
	k_mutex_unlock(&lock);

	bump();
}

void state_disarm(void)
{
	k_mutex_lock(&lock, K_FOREVER);
	armed = false;
	k_mutex_unlock(&lock);

	bump();
}

bool state_armed(void)
{
	bool ret;

	k_mutex_lock(&lock, K_FOREVER);
	ret = armed;
	k_mutex_unlock(&lock);

	return ret;
}

void state_note_get(char *out, size_t len)
{
	k_mutex_lock(&lock, K_FOREVER);
	strncpy(out, note, len - 1);
	out[len - 1] = '\0';
	k_mutex_unlock(&lock);
}

uint32_t state_seq(void)
{
	return (uint32_t)atomic_get(&seq);
}
```

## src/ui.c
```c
/*
 * Copyright The Zephyr Project Contributors
 *
 * SPDX-License-Identifier: Apache-2.0
 */

#include <lvgl.h>
#include <zephyr/device.h>
#include <zephyr/drivers/display.h>
#include <zephyr/kernel.h>

#include <zephyr/logging/log.h>
LOG_MODULE_REGISTER(ui, LOG_LEVEL_INF);

#include "agent_pad.h"

#define OLED_W	 128
#define HEADER_H 14
#define SLOT_W	 20
#define SLOT_H	 26
#define SLOT_Y	 17

#ifdef CONFIG_AGENT_PAD_SIM
lv_obj_t *sim_build(lv_obj_t *root);
#else
LV_FONT_DECLARE(agent_pad_font_12);
#endif

static const struct device *display = DEVICE_DT_GET(DT_CHOSEN(zephyr_display));

static lv_obj_t *layer_label;
static lv_obj_t *page_label;
static lv_obj_t *slots[AGENT_SLOTS];
static lv_obj_t *slot_labels[AGENT_SLOTS];
static lv_obj_t *note_label;

static const char *status_text(enum agent_status status, int tick)
{
	static const char *const spinner[] = {"|", "/", "-", "\\"};

	switch (status) {
	case AGENT_IDLE:
		return "-";
	case AGENT_THINKING:
		return spinner[tick % 4];
	case AGENT_DONE:
		return LV_SYMBOL_OK;
	case AGENT_INPUT:
		return LV_SYMBOL_BELL;
	case AGENT_ERROR:
		return LV_SYMBOL_WARNING;
	default:
		return "";
	}
}

static void refresh(int tick)
{
	char note[NOTE_LEN];
	struct agent agent;
	bool armed = state_armed();

	lv_label_set_text(layer_label, layers[state_layer()].name);
	lv_label_set_text_fmt(page_label, "L%d", state_layer() + 1);

	for (int i = 0; i < AGENT_SLOTS; i++) {
		bool alert;

		state_agent_get(i, &agent);
		alert = agent.status == AGENT_INPUT || agent.status == AGENT_ERROR;

		lv_label_set_text(slot_labels[i], status_text(agent.status, tick));
		lv_obj_set_style_bg_opa(slots[i], alert ? LV_OPA_COVER : LV_OPA_TRANSP, 0);
		lv_obj_set_style_text_color(slot_labels[i],
					    alert ? lv_color_black() : lv_color_white(), 0);
		lv_obj_set_style_border_opa(
			slots[i], agent.status == AGENT_EMPTY ? LV_OPA_TRANSP : LV_OPA_COVER, 0);
	}

	state_note_get(note, sizeof(note));
	lv_label_set_text(note_label, note);

	/* An armed command reads out inverted until it is confirmed. */
	lv_obj_set_style_bg_opa(note_label, armed ? LV_OPA_COVER : LV_OPA_TRANSP, 0);
	lv_obj_set_style_text_color(note_label, armed ? lv_color_black() : lv_color_white(), 0);
}

static lv_obj_t *make_box(lv_obj_t *parent)
{
	lv_obj_t *obj = lv_obj_create(parent);

	lv_obj_remove_style_all(obj);
	return obj;
}

static void build_screen(void)
{
	lv_obj_t *scr = lv_screen_active();
	lv_obj_t *header;

#ifdef CONFIG_AGENT_PAD_SIM
	scr = sim_build(scr);
#endif

	lv_obj_set_style_bg_color(scr, lv_color_black(), 0);
	lv_obj_set_style_bg_opa(scr, LV_OPA_COVER, 0);
	lv_obj_set_style_text_color(scr, lv_color_white(), 0);
#ifndef CONFIG_AGENT_PAD_SIM
	/*
	 * The OLED has no grey levels, so an antialiased font would lose
	 * thin stems to thresholding in whichever polarity it is drawn.
	 */
	lv_obj_set_style_text_font(scr, &agent_pad_font_12, 0);
#endif

	header = make_box(scr);
	lv_obj_set_pos(header, 0, 0);
	lv_obj_set_size(header, OLED_W, HEADER_H);
	lv_obj_set_style_bg_color(header, lv_color_white(), 0);
	lv_obj_set_style_bg_opa(header, LV_OPA_COVER, 0);
	lv_obj_set_style_text_color(header, lv_color_black(), 0);

	layer_label = lv_label_create(header);
	lv_obj_align(layer_label, LV_ALIGN_LEFT_MID, 2, 0);

	page_label = lv_label_create(header);
	lv_obj_align(page_label, LV_ALIGN_RIGHT_MID, -2, 0);

	for (int i = 0; i < AGENT_SLOTS; i++) {
		slots[i] = make_box(scr);
		lv_obj_set_pos(slots[i], 2 + i * (SLOT_W + 1), SLOT_Y);
		lv_obj_set_size(slots[i], SLOT_W, SLOT_H);
		lv_obj_set_style_border_width(slots[i], 1, 0);
		lv_obj_set_style_border_color(slots[i], lv_color_white(), 0);
		lv_obj_set_style_bg_color(slots[i], lv_color_white(), 0);
		lv_obj_set_style_radius(slots[i], 3, 0);

		slot_labels[i] = lv_label_create(slots[i]);
		lv_obj_center(slot_labels[i]);
	}

	note_label = lv_label_create(scr);
	lv_obj_set_pos(note_label, 2, SLOT_Y + SLOT_H + 4);
	lv_obj_set_width(note_label, OLED_W - 4);
	lv_obj_set_style_bg_color(note_label, lv_color_white(), 0);
	lv_obj_set_style_pad_hor(note_label, 1, 0);
	lv_label_set_long_mode(note_label, LV_LABEL_LONG_SCROLL_CIRCULAR);
}

static void ui_thread(void *p1, void *p2, void *p3)
{
	uint32_t seen = ~0U;
	uint32_t iter = 0;
	int tick = 0;

	while (true) {
		struct agent agent;
		bool thinking = false;

		for (int i = 0; i < AGENT_SLOTS; i++) {
			state_agent_get(i, &agent);
			thinking = thinking || (agent.status == AGENT_THINKING);
		}

		if (state_seq() != seen || (thinking && (iter % 4) == 0)) {
			seen = state_seq();
			refresh(tick++);
		}

		lv_timer_handler();
		iter++;
		k_msleep(50);
	}
}

K_THREAD_DEFINE(ui_tid, 4096, ui_thread, NULL, NULL, NULL, 8, 0, K_TICKS_FOREVER);

int ui_init(void)
{
	if (!device_is_ready(display)) {
		LOG_ERR("Display device not ready");
		return -EIO;
	}

	build_screen();
	state_note_set("agents ready");
	display_blanking_off(display);

	k_thread_start(ui_tid);

	return 0;
}
```
